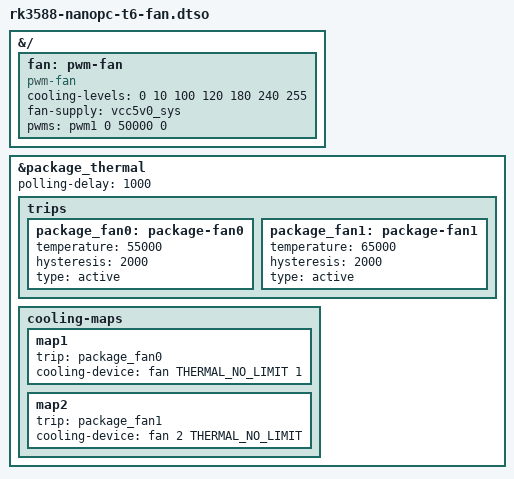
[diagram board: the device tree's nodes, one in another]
// SPDX-License-Identifier: (GPL-2.0+ OR MIT)
/dts-v1/;
/plugin/;

#include <dt-bindings/thermal/thermal.h>

&{/} {
	fan: pwm-fan {
		compatible = "pwm-fan";
		cooling-levels = <0 10 100 120 180 240 255>;
		fan-supply = <&vcc5v0_sys>;
		pwms = <&pwm1 0 50000 0>;
		#cooling-cells = <2>;
	};
};

&package_thermal {
	polling-delay = <1000>;

	trips {
		package_fan0: package-fan0 {
			temperature = <55000>;
			hysteresis = <2000>;
			type = "active";
		};

		package_fan1: package-fan1 {
			temperature = <65000>;
			hysteresis = <2000>;
			type = "active";
		};
	};

	cooling-maps {
		map1 {
			trip = <&package_fan0>;
			cooling-device = <&fan THERMAL_NO_LIMIT 1>;
		};

		map2 {
			trip = <&package_fan1>;
			cooling-device = <&fan 2 THERMAL_NO_LIMIT>;
		};
	};
};
